# CC3200 register map
Vendor: Texas Instruments; Series: SimpleLink; File version: 1.0
CPU: CM4 r0p1, little endian, MPU, no FPU, 3 interrupt priority bits
Registers are 32-bit, read-write, reset 0x0 unless marked. A register's access mark holds for its fields unless they carry their own. Offsets are from the block's base; [hi:lo] are bit positions; {n}, {i} and the like mark numbered series.

## APPS_RCM — ARCM
Base 0x44025000
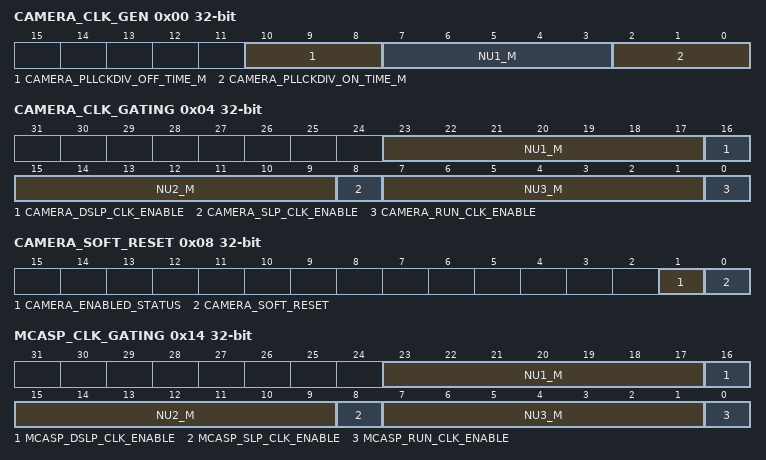
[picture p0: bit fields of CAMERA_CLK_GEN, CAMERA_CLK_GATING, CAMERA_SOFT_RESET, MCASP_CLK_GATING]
0x00 CAMERA_CLK_GEN — APPS_RCM_CAMERA_CLK_GEN
  [10:8] CAMERA_PLLCKDIV_OFF_TIME_M — APPS_RCM_CAMERA_CLK_GEN
  [7:3] NU1_M — APPS_RCM_CAMERA_CLK_GEN
  [2:0] CAMERA_PLLCKDIV_ON_TIME_M — APPS_RCM_CAMERA_CLK_GEN
0x04 CAMERA_CLK_GATING — APPS_RCM_CAMERA_CLK_GATING
  [23:17] NU1_M — APPS_RCM_CAMERA_CLK_GATING
  [16] CAMERA_DSLP_CLK_ENABLE — APPS_RCM_CAMERA_CLK_GATING
  [15:9] NU2_M — APPS_RCM_CAMERA_CLK_GATING
  [8] CAMERA_SLP_CLK_ENABLE — APPS_RCM_CAMERA_CLK_GATING
  [7:1] NU3_M — APPS_RCM_CAMERA_CLK_GATING
  [0] CAMERA_RUN_CLK_ENABLE — APPS_RCM_CAMERA_CLK_GATING
0x08 CAMERA_SOFT_RESET — APPS_RCM_CAMERA_SOFT_RESET
  [1] CAMERA_ENABLED_STATUS — APPS_RCM_CAMERA_SOFT_RESET
  [0] CAMERA_SOFT_RESET — APPS_RCM_CAMERA_SOFT_RESET
0x14 MCASP_CLK_GATING — APPS_RCM_MCASP_CLK_GATING
  [23:17] NU1_M — APPS_RCM_MCASP_CLK_GATING
  [16] MCASP_DSLP_CLK_ENABLE — APPS_RCM_MCASP_CLK_GATING
  [15:9] NU2_M — APPS_RCM_MCASP_CLK_GATING
  [8] MCASP_SLP_CLK_ENABLE — APPS_RCM_MCASP_CLK_GATING
  [7:1] NU3_M — APPS_RCM_MCASP_CLK_GATING
  [0] MCASP_RUN_CLK_ENABLE — APPS_RCM_MCASP_CLK_GATING
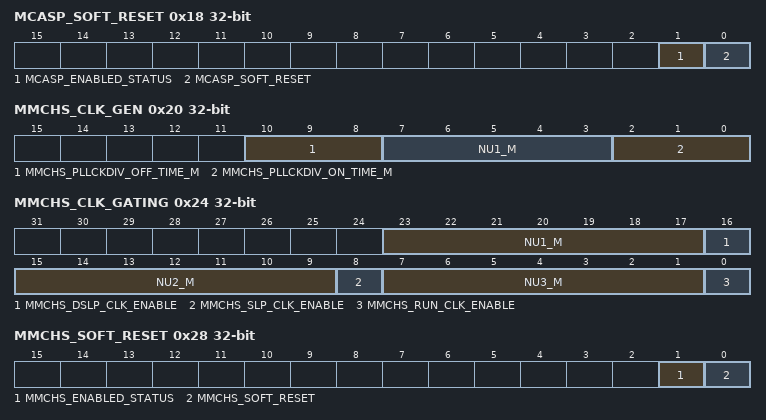
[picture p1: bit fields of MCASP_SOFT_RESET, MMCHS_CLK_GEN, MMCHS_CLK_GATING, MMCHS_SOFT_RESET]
0x18 MCASP_SOFT_RESET — APPS_RCM_MCASP_SOFT_RESET
  [1] MCASP_ENABLED_STATUS — APPS_RCM_MCASP_SOFT_RESET
  [0] MCASP_SOFT_RESET — APPS_RCM_MCASP_SOFT_RESET
0x20 MMCHS_CLK_GEN — APPS_RCM_MMCHS_CLK_GEN
  [10:8] MMCHS_PLLCKDIV_OFF_TIME_M — APPS_RCM_MMCHS_CLK_GEN
  [7:3] NU1_M — APPS_RCM_MMCHS_CLK_GEN
  [2:0] MMCHS_PLLCKDIV_ON_TIME_M — APPS_RCM_MMCHS_CLK_GEN
0x24 MMCHS_CLK_GATING — APPS_RCM_MMCHS_CLK_GATING
  [23:17] NU1_M — APPS_RCM_MMCHS_CLK_GATING
  [16] MMCHS_DSLP_CLK_ENABLE — APPS_RCM_MMCHS_CLK_GATING
  [15:9] NU2_M — APPS_RCM_MMCHS_CLK_GATING
  [8] MMCHS_SLP_CLK_ENABLE — APPS_RCM_MMCHS_CLK_GATING
  [7:1] NU3_M — APPS_RCM_MMCHS_CLK_GATING
  [0] MMCHS_RUN_CLK_ENABLE — APPS_RCM_MMCHS_CLK_GATING
0x28 MMCHS_SOFT_RESET — APPS_RCM_MMCHS_SOFT_RESET
  [1] MMCHS_ENABLED_STATUS — APPS_RCM_MMCHS_SOFT_RESET
  [0] MMCHS_SOFT_RESET — APPS_RCM_MMCHS_SOFT_RESET
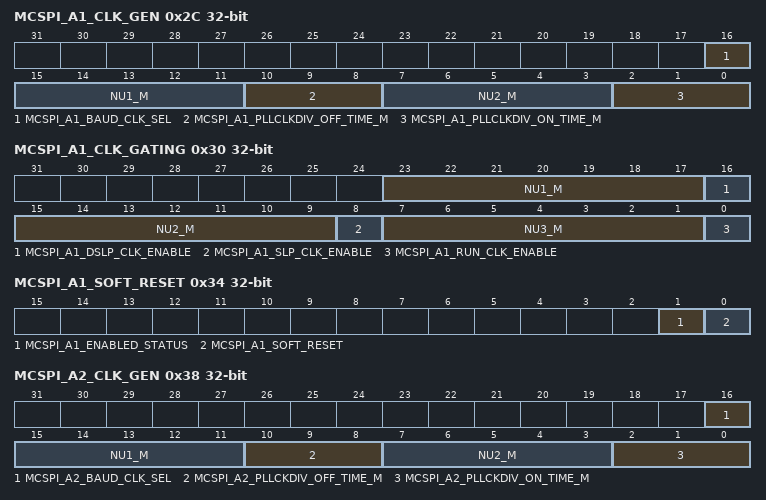
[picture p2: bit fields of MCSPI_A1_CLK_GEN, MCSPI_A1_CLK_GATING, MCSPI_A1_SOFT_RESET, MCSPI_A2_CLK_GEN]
0x2C MCSPI_A1_CLK_GEN — APPS_RCM_MCSPI_A1_CLK_GEN
  [16] MCSPI_A1_BAUD_CLK_SEL — APPS_RCM_MCSPI_A1_CLK_GEN
  [15:11] NU1_M — APPS_RCM_MCSPI_A1_CLK_GEN
  [10:8] MCSPI_A1_PLLCLKDIV_OFF_TIME_M — APPS_RCM_MCSPI_A1_CLK_GEN
  [7:3] NU2_M — APPS_RCM_MCSPI_A1_CLK_GEN
  [2:0] MCSPI_A1_PLLCLKDIV_ON_TIME_M — APPS_RCM_MCSPI_A1_CLK_GEN
0x30 MCSPI_A1_CLK_GATING — APPS_RCM_MCSPI_A1_CLK_GATING
  [23:17] NU1_M — APPS_RCM_MCSPI_A1_CLK_GATING
  [16] MCSPI_A1_DSLP_CLK_ENABLE — APPS_RCM_MCSPI_A1_CLK_GATING
  [15:9] NU2_M — APPS_RCM_MCSPI_A1_CLK_GATING
  [8] MCSPI_A1_SLP_CLK_ENABLE — APPS_RCM_MCSPI_A1_CLK_GATING
  [7:1] NU3_M — APPS_RCM_MCSPI_A1_CLK_GATING
  [0] MCSPI_A1_RUN_CLK_ENABLE — APPS_RCM_MCSPI_A1_CLK_GATING
0x34 MCSPI_A1_SOFT_RESET — APPS_RCM_MCSPI_A1_SOFT_RESET
  [1] MCSPI_A1_ENABLED_STATUS — APPS_RCM_MCSPI_A1_SOFT_RESET
  [0] MCSPI_A1_SOFT_RESET — APPS_RCM_MCSPI_A1_SOFT_RESET
0x38 MCSPI_A2_CLK_GEN — APPS_RCM_MCSPI_A2_CLK_GEN
  [16] MCSPI_A2_BAUD_CLK_SEL — APPS_RCM_MCSPI_A2_CLK_GEN
  [15:11] NU1_M — APPS_RCM_MCSPI_A2_CLK_GEN
  [10:8] MCSPI_A2_PLLCKDIV_OFF_TIME_M — APPS_RCM_MCSPI_A2_CLK_GEN
  [7:3] NU2_M — APPS_RCM_MCSPI_A2_CLK_GEN
  [2:0] MCSPI_A2_PLLCKDIV_ON_TIME_M — APPS_RCM_MCSPI_A2_CLK_GEN
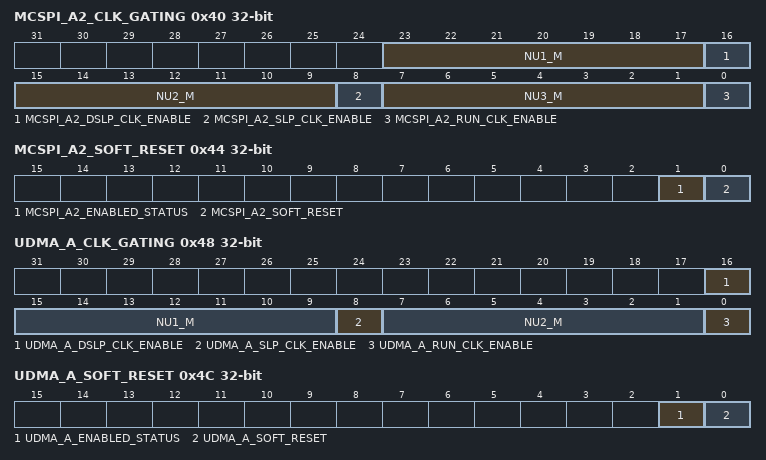
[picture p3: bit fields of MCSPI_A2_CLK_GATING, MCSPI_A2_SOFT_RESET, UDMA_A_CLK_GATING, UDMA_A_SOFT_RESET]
0x40 MCSPI_A2_CLK_GATING — APPS_RCM_MCSPI_A2_CLK_GATING
  [23:17] NU1_M — APPS_RCM_MCSPI_A2_CLK_GATING
  [16] MCSPI_A2_DSLP_CLK_ENABLE — APPS_RCM_MCSPI_A2_CLK_GATING
  [15:9] NU2_M — APPS_RCM_MCSPI_A2_CLK_GATING
  [8] MCSPI_A2_SLP_CLK_ENABLE — APPS_RCM_MCSPI_A2_CLK_GATING
  [7:1] NU3_M — APPS_RCM_MCSPI_A2_CLK_GATING
  [0] MCSPI_A2_RUN_CLK_ENABLE — APPS_RCM_MCSPI_A2_CLK_GATING
0x44 MCSPI_A2_SOFT_RESET — APPS_RCM_MCSPI_A2_SOFT_RESET
  [1] MCSPI_A2_ENABLED_STATUS — APPS_RCM_MCSPI_A2_SOFT_RESET
  [0] MCSPI_A2_SOFT_RESET — APPS_RCM_MCSPI_A2_SOFT_RESET
0x48 UDMA_A_CLK_GATING — APPS_RCM_UDMA_A_CLK_GATING
  [16] UDMA_A_DSLP_CLK_ENABLE — APPS_RCM_UDMA_A_CLK_GATING
  [15:9] NU1_M — APPS_RCM_UDMA_A_CLK_GATING
  [8] UDMA_A_SLP_CLK_ENABLE — APPS_RCM_UDMA_A_CLK_GATING
  [7:1] NU2_M — APPS_RCM_UDMA_A_CLK_GATING
  [0] UDMA_A_RUN_CLK_ENABLE — APPS_RCM_UDMA_A_CLK_GATING
0x4C UDMA_A_SOFT_RESET — APPS_RCM_UDMA_A_SOFT_RESET
  [1] UDMA_A_ENABLED_STATUS — APPS_RCM_UDMA_A_SOFT_RESET
  [0] UDMA_A_SOFT_RESET — APPS_RCM_UDMA_A_SOFT_RESET
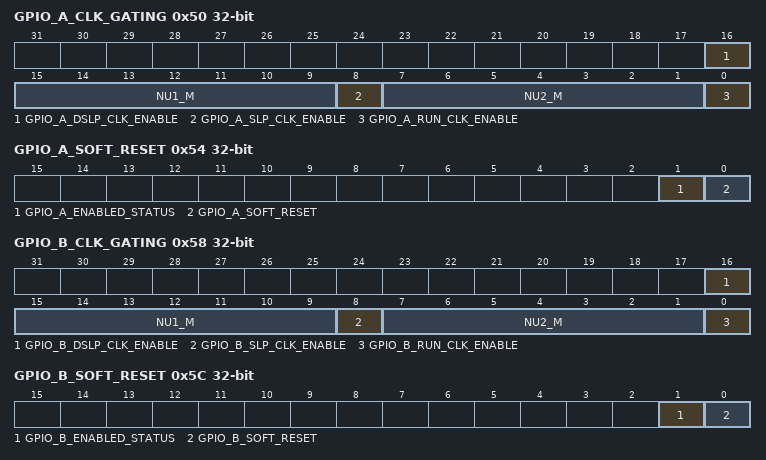
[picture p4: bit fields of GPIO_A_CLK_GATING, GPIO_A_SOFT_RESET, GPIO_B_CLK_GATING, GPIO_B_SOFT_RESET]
0x50 GPIO_A_CLK_GATING — APPS_RCM_GPIO_A_CLK_GATING
  [16] GPIO_A_DSLP_CLK_ENABLE — APPS_RCM_GPIO_A_CLK_GATING
  [15:9] NU1_M — APPS_RCM_GPIO_A_CLK_GATING
  [8] GPIO_A_SLP_CLK_ENABLE — APPS_RCM_GPIO_A_CLK_GATING
  [7:1] NU2_M — APPS_RCM_GPIO_A_CLK_GATING
  [0] GPIO_A_RUN_CLK_ENABLE — APPS_RCM_GPIO_A_CLK_GATING
0x54 GPIO_A_SOFT_RESET — APPS_RCM_GPIO_A_SOFT_RESET
  [1] GPIO_A_ENABLED_STATUS — APPS_RCM_GPIO_A_SOFT_RESET
  [0] GPIO_A_SOFT_RESET — APPS_RCM_GPIO_A_SOFT_RESET
0x58 GPIO_B_CLK_GATING — APPS_RCM_GPIO_B_CLK_GATING
  [16] GPIO_B_DSLP_CLK_ENABLE — APPS_RCM_GPIO_B_CLK_GATING
  [15:9] NU1_M — APPS_RCM_GPIO_B_CLK_GATING
  [8] GPIO_B_SLP_CLK_ENABLE — APPS_RCM_GPIO_B_CLK_GATING
  [7:1] NU2_M — APPS_RCM_GPIO_B_CLK_GATING
  [0] GPIO_B_RUN_CLK_ENABLE — APPS_RCM_GPIO_B_CLK_GATING
0x5C GPIO_B_SOFT_RESET — APPS_RCM_GPIO_B_SOFT_RESET
  [1] GPIO_B_ENABLED_STATUS — APPS_RCM_GPIO_B_SOFT_RESET
  [0] GPIO_B_SOFT_RESET — APPS_RCM_GPIO_B_SOFT_RESET
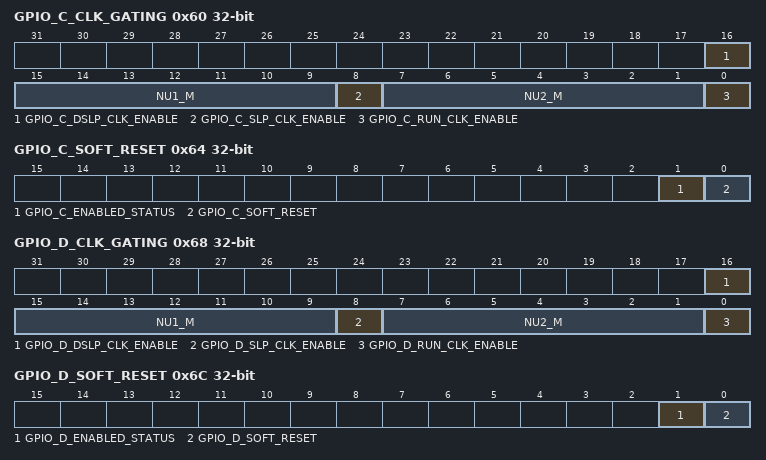
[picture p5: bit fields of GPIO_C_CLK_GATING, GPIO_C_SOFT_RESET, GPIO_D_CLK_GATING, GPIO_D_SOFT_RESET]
0x60 GPIO_C_CLK_GATING — APPS_RCM_GPIO_C_CLK_GATING
  [16] GPIO_C_DSLP_CLK_ENABLE — APPS_RCM_GPIO_C_CLK_GATING
  [15:9] NU1_M — APPS_RCM_GPIO_C_CLK_GATING
  [8] GPIO_C_SLP_CLK_ENABLE — APPS_RCM_GPIO_C_CLK_GATING
  [7:1] NU2_M — APPS_RCM_GPIO_C_CLK_GATING
  [0] GPIO_C_RUN_CLK_ENABLE — APPS_RCM_GPIO_C_CLK_GATING
0x64 GPIO_C_SOFT_RESET — APPS_RCM_GPIO_C_SOFT_RESET
  [1] GPIO_C_ENABLED_STATUS — APPS_RCM_GPIO_C_SOFT_RESET
  [0] GPIO_C_SOFT_RESET — APPS_RCM_GPIO_C_SOFT_RESET
0x68 GPIO_D_CLK_GATING — APPS_RCM_GPIO_D_CLK_GATING
  [16] GPIO_D_DSLP_CLK_ENABLE — APPS_RCM_GPIO_D_CLK_GATING
  [15:9] NU1_M — APPS_RCM_GPIO_D_CLK_GATING
  [8] GPIO_D_SLP_CLK_ENABLE — APPS_RCM_GPIO_D_CLK_GATING
  [7:1] NU2_M — APPS_RCM_GPIO_D_CLK_GATING
  [0] GPIO_D_RUN_CLK_ENABLE — APPS_RCM_GPIO_D_CLK_GATING
0x6C GPIO_D_SOFT_RESET — APPS_RCM_GPIO_D_SOFT_RESET
  [1] GPIO_D_ENABLED_STATUS — APPS_RCM_GPIO_D_SOFT_RESET
  [0] GPIO_D_SOFT_RESET — APPS_RCM_GPIO_D_SOFT_RESET
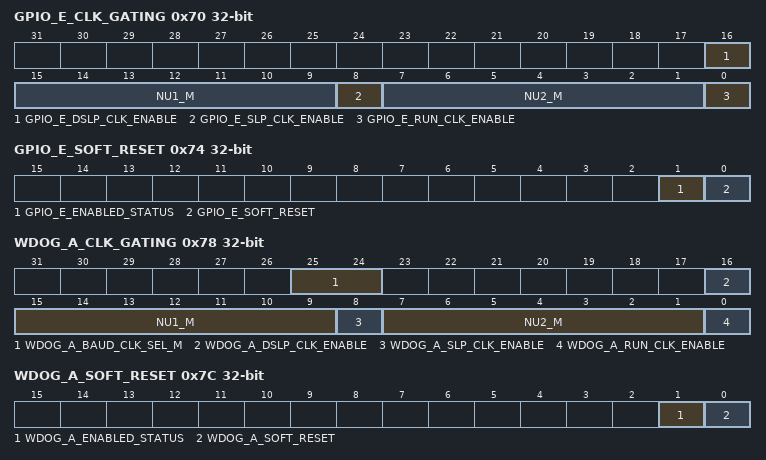
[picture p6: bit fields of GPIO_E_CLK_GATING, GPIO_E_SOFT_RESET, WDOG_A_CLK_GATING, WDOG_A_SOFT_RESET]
0x70 GPIO_E_CLK_GATING — APPS_RCM_GPIO_E_CLK_GATING
  [16] GPIO_E_DSLP_CLK_ENABLE — APPS_RCM_GPIO_E_CLK_GATING
  [15:9] NU1_M — APPS_RCM_GPIO_E_CLK_GATING
  [8] GPIO_E_SLP_CLK_ENABLE — APPS_RCM_GPIO_E_CLK_GATING
  [7:1] NU2_M — APPS_RCM_GPIO_E_CLK_GATING
  [0] GPIO_E_RUN_CLK_ENABLE — APPS_RCM_GPIO_E_CLK_GATING
0x74 GPIO_E_SOFT_RESET — APPS_RCM_GPIO_E_SOFT_RESET
  [1] GPIO_E_ENABLED_STATUS — APPS_RCM_GPIO_E_SOFT_RESET
  [0] GPIO_E_SOFT_RESET — APPS_RCM_GPIO_E_SOFT_RESET
0x78 WDOG_A_CLK_GATING — APPS_RCM_WDOG_A_CLK_GATING
  [25:24] WDOG_A_BAUD_CLK_SEL_M — APPS_RCM_WDOG_A_CLK_GATING
  [16] WDOG_A_DSLP_CLK_ENABLE — APPS_RCM_WDOG_A_CLK_GATING
  [15:9] NU1_M — APPS_RCM_WDOG_A_CLK_GATING
  [8] WDOG_A_SLP_CLK_ENABLE — APPS_RCM_WDOG_A_CLK_GATING
  [7:1] NU2_M — APPS_RCM_WDOG_A_CLK_GATING
  [0] WDOG_A_RUN_CLK_ENABLE — APPS_RCM_WDOG_A_CLK_GATING
0x7C WDOG_A_SOFT_RESET — APPS_RCM_WDOG_A_SOFT_RESET
  [1] WDOG_A_ENABLED_STATUS — APPS_RCM_WDOG_A_SOFT_RESET
  [0] WDOG_A_SOFT_RESET — APPS_RCM_WDOG_A_SOFT_RESET
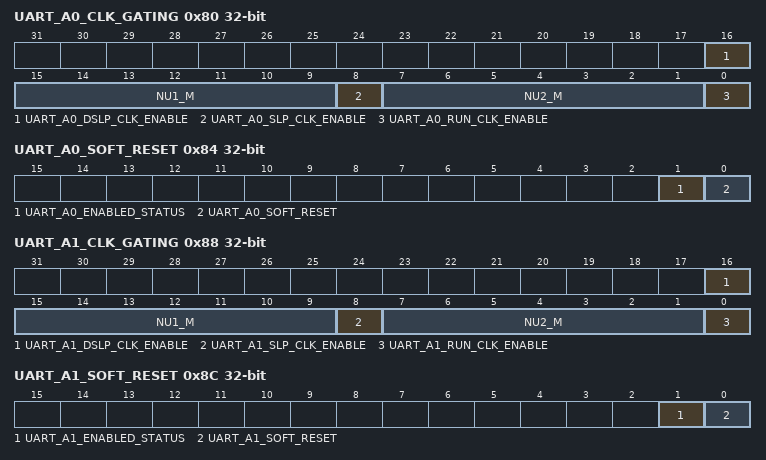
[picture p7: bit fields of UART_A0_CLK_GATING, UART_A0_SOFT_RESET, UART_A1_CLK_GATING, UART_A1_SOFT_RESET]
0x80 UART_A0_CLK_GATING — APPS_RCM_UART_A0_CLK_GATING
  [16] UART_A0_DSLP_CLK_ENABLE — APPS_RCM_UART_A0_CLK_GATING
  [15:9] NU1_M — APPS_RCM_UART_A0_CLK_GATING
  [8] UART_A0_SLP_CLK_ENABLE — APPS_RCM_UART_A0_CLK_GATING
  [7:1] NU2_M — APPS_RCM_UART_A0_CLK_GATING
  [0] UART_A0_RUN_CLK_ENABLE — APPS_RCM_UART_A0_CLK_GATING
0x84 UART_A0_SOFT_RESET — APPS_RCM_UART_A0_SOFT_RESET
  [1] UART_A0_ENABLED_STATUS — APPS_RCM_UART_A0_SOFT_RESET
  [0] UART_A0_SOFT_RESET — APPS_RCM_UART_A0_SOFT_RESET
0x88 UART_A1_CLK_GATING — APPS_RCM_UART_A1_CLK_GATING
  [16] UART_A1_DSLP_CLK_ENABLE — APPS_RCM_UART_A1_CLK_GATING
  [15:9] NU1_M — APPS_RCM_UART_A1_CLK_GATING
  [8] UART_A1_SLP_CLK_ENABLE — APPS_RCM_UART_A1_CLK_GATING
  [7:1] NU2_M — APPS_RCM_UART_A1_CLK_GATING
  [0] UART_A1_RUN_CLK_ENABLE — APPS_RCM_UART_A1_CLK_GATING
0x8C UART_A1_SOFT_RESET — APPS_RCM_UART_A1_SOFT_RESET
  [1] UART_A1_ENABLED_STATUS — APPS_RCM_UART_A1_SOFT_RESET
  [0] UART_A1_SOFT_RESET — APPS_RCM_UART_A1_SOFT_RESET
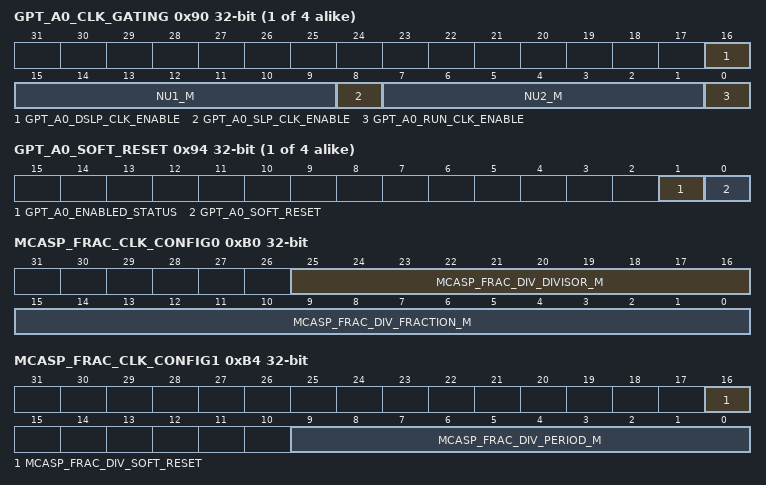
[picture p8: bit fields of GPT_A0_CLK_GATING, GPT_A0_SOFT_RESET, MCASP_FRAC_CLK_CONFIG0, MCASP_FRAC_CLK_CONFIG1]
{0x90+8i} GPT_A{i}_CLK_GATING (i=0..3) — APPS_RCM_GPT_A{i}_CLK_GATING
  [16] GPT_A{i}_DSLP_CLK_ENABLE — APPS_RCM_GPT_A{i}_CLK_GATING
  [15:9] NU1_M — APPS_RCM_GPT_A{i}_CLK_GATING
  [8] GPT_A{i}_SLP_CLK_ENABLE — APPS_RCM_GPT_A{i}_CLK_GATING
  [7:1] NU2_M — APPS_RCM_GPT_A{i}_CLK_GATING
  [0] GPT_A{i}_RUN_CLK_ENABLE — APPS_RCM_GPT_A{i}_CLK_GATING
{0x94+8i} GPT_A{i}_SOFT_RESET (i=0..3) — APPS_RCM_GPT_A{i}_SOFT_RESET
  [1] GPT_A{i}_ENABLED_STATUS — APPS_RCM_GPT_A{i}_SOFT_RESET
  [0] GPT_A{i}_SOFT_RESET — APPS_RCM_GPT_A{i}_SOFT_RESET
0xB0 MCASP_FRAC_CLK_CONFIG0 — APPS_RCM_MCASP_FRAC_CLK_CONFIG0
  [25:16] MCASP_FRAC_DIV_DIVISOR_M — APPS_RCM_MCASP_FRAC_CLK_CONFIG0
  [15:0] MCASP_FRAC_DIV_FRACTION_M — APPS_RCM_MCASP_FRAC_CLK_CONFIG0
0xB4 MCASP_FRAC_CLK_CONFIG1 — APPS_RCM_MCASP_FRAC_CLK_CONFIG1
  [16] MCASP_FRAC_DIV_SOFT_RESET — APPS_RCM_MCASP_FRAC_CLK_CONFIG1
  [9:0] MCASP_FRAC_DIV_PERIOD_M — APPS_RCM_MCASP_FRAC_CLK_CONFIG1
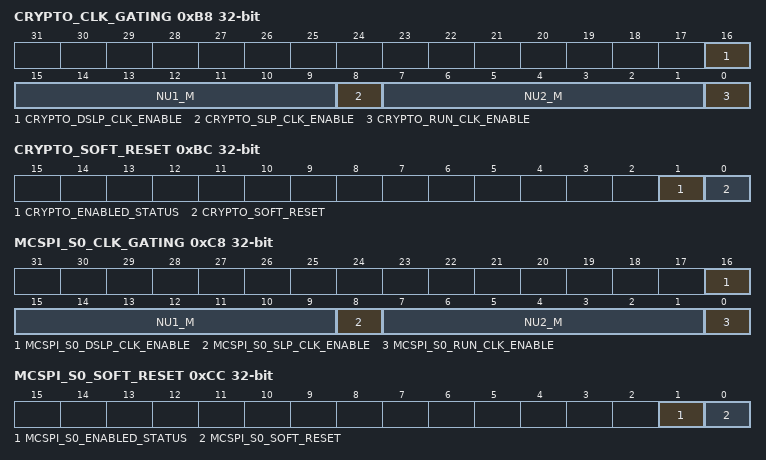
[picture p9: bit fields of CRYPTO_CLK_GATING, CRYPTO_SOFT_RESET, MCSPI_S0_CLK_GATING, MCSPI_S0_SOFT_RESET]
0xB8 CRYPTO_CLK_GATING — APPS_RCM_CRYPTO_CLK_GATING
  [16] CRYPTO_DSLP_CLK_ENABLE — APPS_RCM_CRYPTO_CLK_GATING
  [15:9] NU1_M — APPS_RCM_CRYPTO_CLK_GATING
  [8] CRYPTO_SLP_CLK_ENABLE — APPS_RCM_CRYPTO_CLK_GATING
  [7:1] NU2_M — APPS_RCM_CRYPTO_CLK_GATING
  [0] CRYPTO_RUN_CLK_ENABLE — APPS_RCM_CRYPTO_CLK_GATING
0xBC CRYPTO_SOFT_RESET — APPS_RCM_CRYPTO_SOFT_RESET
  [1] CRYPTO_ENABLED_STATUS — APPS_RCM_CRYPTO_SOFT_RESET
  [0] CRYPTO_SOFT_RESET — APPS_RCM_CRYPTO_SOFT_RESET
0xC8 MCSPI_S0_CLK_GATING — APPS_RCM_MCSPI_S0_CLK_GATING
  [16] MCSPI_S0_DSLP_CLK_ENABLE — APPS_RCM_MCSPI_S0_CLK_GATING
  [15:9] NU1_M — APPS_RCM_MCSPI_S0_CLK_GATING
  [8] MCSPI_S0_SLP_CLK_ENABLE — APPS_RCM_MCSPI_S0_CLK_GATING
  [7:1] NU2_M — APPS_RCM_MCSPI_S0_CLK_GATING
  [0] MCSPI_S0_RUN_CLK_ENABLE — APPS_RCM_MCSPI_S0_CLK_GATING
0xCC MCSPI_S0_SOFT_RESET — APPS_RCM_MCSPI_S0_SOFT_RESET
  [1] MCSPI_S0_ENABLED_STATUS — APPS_RCM_MCSPI_S0_SOFT_RESET
  [0] MCSPI_S0_SOFT_RESET — APPS_RCM_MCSPI_S0_SOFT_RESET
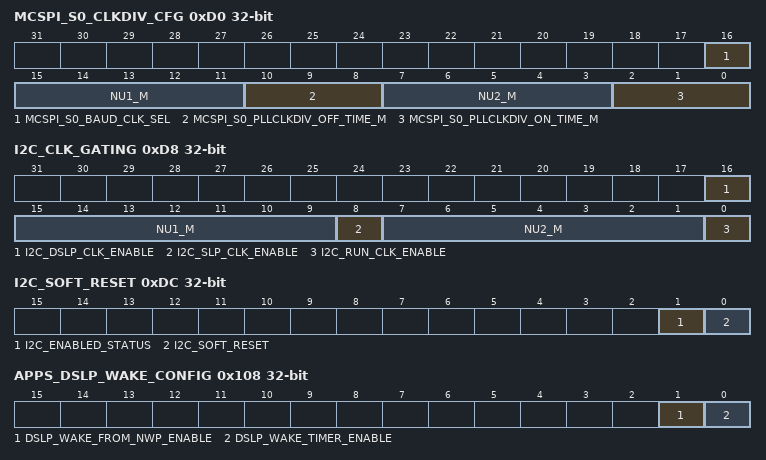
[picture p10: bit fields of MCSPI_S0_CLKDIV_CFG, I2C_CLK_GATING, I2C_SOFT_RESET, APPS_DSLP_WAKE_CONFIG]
0xD0 MCSPI_S0_CLKDIV_CFG — APPS_RCM_MCSPI_S0_CLKDIV_CFG
  [16] MCSPI_S0_BAUD_CLK_SEL — APPS_RCM_MCSPI_S0_CLKDIV_CFG
  [15:11] NU1_M — APPS_RCM_MCSPI_S0_CLKDIV_CFG
  [10:8] MCSPI_S0_PLLCLKDIV_OFF_TIME_M — APPS_RCM_MCSPI_S0_CLKDIV_CFG
  [7:3] NU2_M — APPS_RCM_MCSPI_S0_CLKDIV_CFG
  [2:0] MCSPI_S0_PLLCLKDIV_ON_TIME_M — APPS_RCM_MCSPI_S0_CLKDIV_CFG
0xD8 I2C_CLK_GATING — APPS_RCM_I2C_CLK_GATING
  [16] I2C_DSLP_CLK_ENABLE — APPS_RCM_I2C_CLK_GATING
  [15:9] NU1_M — APPS_RCM_I2C_CLK_GATING
  [8] I2C_SLP_CLK_ENABLE — APPS_RCM_I2C_CLK_GATING
  [7:1] NU2_M — APPS_RCM_I2C_CLK_GATING
  [0] I2C_RUN_CLK_ENABLE — APPS_RCM_I2C_CLK_GATING
0xDC I2C_SOFT_RESET — APPS_RCM_I2C_SOFT_RESET
  [1] I2C_ENABLED_STATUS — APPS_RCM_I2C_SOFT_RESET
  [0] I2C_SOFT_RESET — APPS_RCM_I2C_SOFT_RESET
0xE4 APPS_LPDS_REQ — APPS_RCM_APPS_LPDS_REQ
  [0] APPS_LPDS_REQ
0xEC APPS_TURBO_REQ — APPS_RCM_APPS_TURBO_REQ
  [0] APPS_TURBO_REQ
0x108 APPS_DSLP_WAKE_CONFIG — APPS_RCM_APPS_DSLP_WAKE_CONFIG
  [1] DSLP_WAKE_FROM_NWP_ENABLE — APPS_RCM_APPS_DSLP_WAKE_CONFIG
  [0] DSLP_WAKE_TIMER_ENABLE — APPS_RCM_APPS_DSLP_WAKE_CONFIG
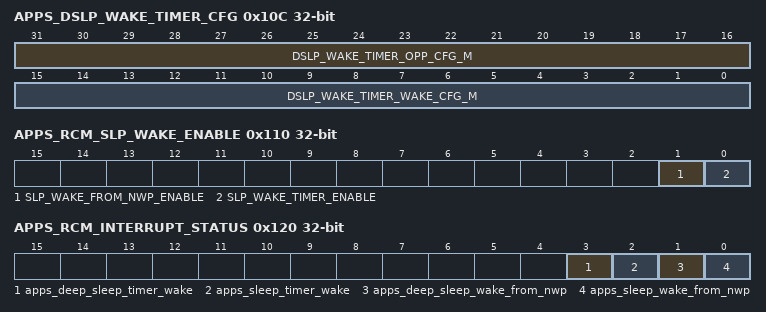
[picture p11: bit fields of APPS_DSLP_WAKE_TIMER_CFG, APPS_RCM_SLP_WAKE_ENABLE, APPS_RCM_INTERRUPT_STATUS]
0x10C APPS_DSLP_WAKE_TIMER_CFG — APPS_RCM_APPS_DSLP_WAKE_TIMER_CFG
  [31:16] DSLP_WAKE_TIMER_OPP_CFG_M — APPS_RCM_APPS_DSLP_WAKE_TIMER_CFG
  [15:0] DSLP_WAKE_TIMER_WAKE_CFG_M — APPS_RCM_APPS_DSLP_WAKE_TIMER_CFG
0x110 APPS_RCM_SLP_WAKE_ENABLE — APPS_RCM_APPS_RCM_SLP_WAKE_ENABLE
  [1] SLP_WAKE_FROM_NWP_ENABLE — APPS_RCM_APPS_RCM_SLP_WAKE_ENABLE
  [0] SLP_WAKE_TIMER_ENABLE — APPS_RCM_APPS_RCM_SLP_WAKE_ENABLE
0x114 APPS_SLP_WAKETIMER_CFG — APPS_RCM_APPS_SLP_WAKETIMER_CFG
  [31:0] SLP_WAKE_TIMER_CFG_M
0x118 APPS_TO_NWP_WAKE_REQUEST — APPS_RCM_APPS_TO_NWP_WAKE_REQUEST
  [0] APPS_TO_NWP_WAKEUP_REQUEST
0x120 APPS_RCM_INTERRUPT_STATUS — APPS_RCM_APPS_RCM_INTERRUPT_STATUS
  [3] apps_deep_sleep_timer_wake — APPS_RCM_APPS_RCM_INTERRUPT_STATUS
  [2] apps_sleep_timer_wake — APPS_RCM_APPS_RCM_INTERRUPT_STATUS
  [1] apps_deep_sleep_wake_from_nwp — APPS_RCM_APPS_RCM_INTERRUPT_STATUS
  [0] apps_sleep_wake_from_nwp — APPS_RCM_APPS_RCM_INTERRUPT_STATUS
0x124 APPS_RCM_INTERRUPT_ENABLE — APPS_RCM_APPS_RCM_INTERRUPT_ENABLE
